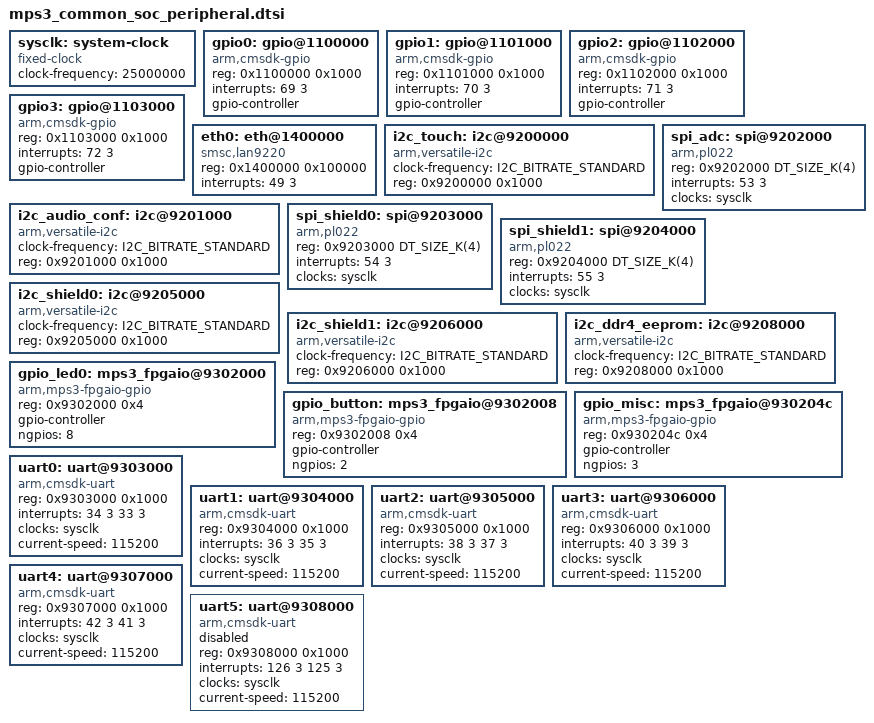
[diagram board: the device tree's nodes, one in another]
/*
 * Copyright (c) 2019-2021 Linaro Limited
 * Copyright 2024 Arm Limited and/or its affiliates <open-source-office@arm.com>
 *
 * SPDX-License-Identifier: Apache-2.0
 */

sysclk: system-clock {
	compatible = "fixed-clock";
	clock-frequency = <25000000>;
	#clock-cells = <0>;
};

gpio0: gpio@1100000 {
	compatible = "arm,cmsdk-gpio";
	reg = <0x1100000 0x1000>;
	interrupts = <69 3>;
	gpio-controller;
	#gpio-cells = <2>;
};

gpio1: gpio@1101000 {
	compatible = "arm,cmsdk-gpio";
	reg = <0x1101000 0x1000>;
	interrupts = <70 3>;
	gpio-controller;
	#gpio-cells = <2>;
};

gpio2: gpio@1102000 {
	compatible = "arm,cmsdk-gpio";
	reg = <0x1102000 0x1000>;
	interrupts = <71 3>;
	gpio-controller;
	#gpio-cells = <2>;
};

gpio3: gpio@1103000 {
	compatible = "arm,cmsdk-gpio";
	reg = <0x1103000 0x1000>;
	interrupts = <72 3>;
	gpio-controller;
	#gpio-cells = <2>;
};

eth0: eth@1400000 {
	/* Linux has "smsc,lan9115" */
	compatible = "smsc,lan9220";
	/* Actual reg range is ~0x200 */
	reg = <0x1400000 0x100000>;
	interrupts = <49 3>;
};

i2c_touch: i2c@9200000 {
	compatible = "arm,versatile-i2c";
	clock-frequency = <I2C_BITRATE_STANDARD>;
	#address-cells = <1>;
	#size-cells = <0>;
	reg = <0x9200000 0x1000>;
};

i2c_audio_conf: i2c@9201000 {
	compatible = "arm,versatile-i2c";
	clock-frequency = <I2C_BITRATE_STANDARD>;
	#address-cells = <1>;
	#size-cells = <0>;
	reg = <0x9201000 0x1000>;
};

spi_adc: spi@9202000 {
	compatible = "arm,pl022";
	reg = <0x9202000 DT_SIZE_K(4)>;
	interrupts = <53 3>;
	interrupt-names = "shield_adc";
	clocks = <&sysclk>;
	#address-cells = <1>;
	#size-cells = <0>;
};

spi_shield0: spi@9203000 {
	compatible = "arm,pl022";
	reg = <0x9203000 DT_SIZE_K(4)>;
	interrupts = <54 3>;
	interrupt-names = "shield0_spi";
	clocks = <&sysclk>;
	#address-cells = <1>;
	#size-cells = <0>;
};

spi_shield1: spi@9204000 {
	compatible = "arm,pl022";
	reg = <0x9204000 DT_SIZE_K(4)>;
	interrupts = <55 3>;
	interrupt-names = "shield1_spi";
	clocks = <&sysclk>;
	#address-cells = <1>;
	#size-cells = <0>;
};

i2c_shield0: i2c@9205000 {
	compatible = "arm,versatile-i2c";
	clock-frequency = <I2C_BITRATE_STANDARD>;
	#address-cells = <1>;
	#size-cells = <0>;
	reg = <0x9205000 0x1000>;
};

i2c_shield1: i2c@9206000 {
	compatible = "arm,versatile-i2c";
	clock-frequency = <I2C_BITRATE_STANDARD>;
	#address-cells = <1>;
	#size-cells = <0>;
	reg = <0x9206000 0x1000>;
};

i2c_ddr4_eeprom: i2c@9208000 {
	compatible = "arm,versatile-i2c";
	clock-frequency = <I2C_BITRATE_STANDARD>;
	#address-cells = <1>;
	#size-cells = <0>;
	reg = <0x9208000 0x1000>;
};

gpio_led0: mps3_fpgaio@9302000 {
	compatible = "arm,mps3-fpgaio-gpio";

	reg = <0x9302000 0x4>;
	gpio-controller;
	#gpio-cells = <1>;
	ngpios = <8>;
};

gpio_button: mps3_fpgaio@9302008 {
	compatible = "arm,mps3-fpgaio-gpio";

	reg = <0x9302008 0x4>;
	gpio-controller;
	#gpio-cells = <1>;
	ngpios = <2>;
};

gpio_misc: mps3_fpgaio@930204c {
	compatible = "arm,mps3-fpgaio-gpio";

	reg = <0x930204c 0x4>;
	gpio-controller;
	#gpio-cells = <1>;
	ngpios = <3>;
};

uart0: uart@9303000 {
	compatible = "arm,cmsdk-uart";
	reg = <0x9303000 0x1000>;
	interrupts = <34 3 33 3>;
	interrupt-names = "tx", "rx";
	clocks = <&sysclk>;
	current-speed = <115200>;
};

uart1: uart@9304000 {
	compatible = "arm,cmsdk-uart";
	reg = <0x9304000 0x1000>;
	interrupts = <36 3 35 3>;
	interrupt-names = "tx", "rx";
	clocks = <&sysclk>;
	current-speed = <115200>;
};

uart2: uart@9305000 {
	compatible = "arm,cmsdk-uart";
	reg = <0x9305000 0x1000>;
	interrupts = <38 3 37 3>;
	interrupt-names = "tx", "rx";
	clocks = <&sysclk>;
	current-speed = <115200>;
};

uart3: uart@9306000 {
	compatible = "arm,cmsdk-uart";
	reg = <0x9306000 0x1000>;
	interrupts = <40 3 39 3>;
	interrupt-names = "tx", "rx";
	clocks = <&sysclk>;
	current-speed = <115200>;
};

uart4: uart@9307000 {
	compatible = "arm,cmsdk-uart";
	reg = <0x9307000 0x1000>;
	interrupts = <42 3 41 3>;
	interrupt-names = "tx", "rx";
	clocks = <&sysclk>;
	current-speed = <115200>;
};

uart5: uart@9308000 {
	compatible = "arm,cmsdk-uart";
	status = "disabled";
	reg = <0x9308000 0x1000>;
	interrupt-names = "tx", "rx";
	interrupts = <126 3 125 3>;
	clocks = <&sysclk>;
	current-speed = <115200>;
};
